# ipro7 register map
Vendor: intelpro; Series: BTBLE
CPU: ipro7, little endian
Registers are 32-bit, read-write, reset 0x0 unless marked. A register's access mark holds for its fields unless they carry their own. Offsets are from the block's base; [hi:lo] are bit positions; {n}, {i} and the like mark numbered series.

## SF_CTRL
Base 0x30081000
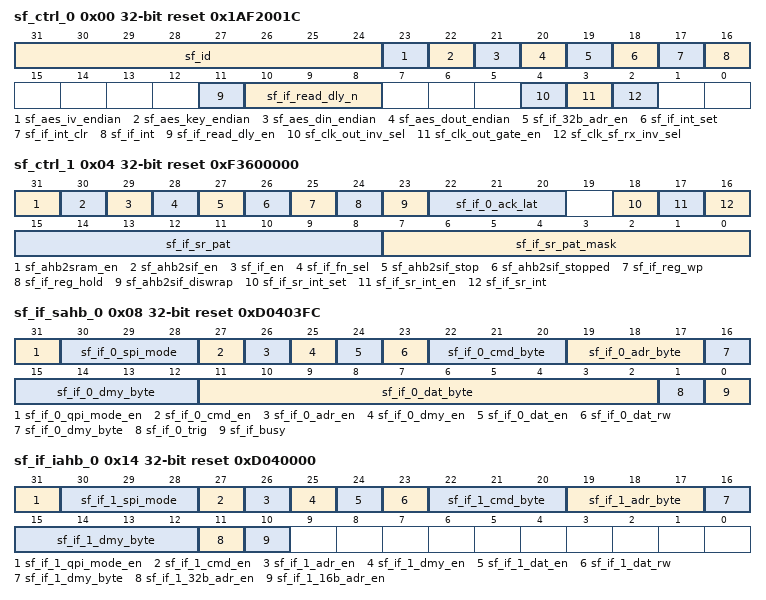
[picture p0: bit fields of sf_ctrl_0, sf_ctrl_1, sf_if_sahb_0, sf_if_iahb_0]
0x00 sf_ctrl_0 reset 0x1AF2001C (reset mask 0xFFFEFFFF)
  [31:24] sf_id — ID
  [23] sf_aes_iv_endian — 0:little-endian 1:big-endian
  [22] sf_aes_key_endian — 0:little-endian 1:big-endian
  [21] sf_aes_din_endian — 0:little-endian 1:big-endian
  [20] sf_aes_dout_endian — 0:little-endian 1:big-endian
  [19] sf_if_32b_adr_en — 1: enable 32-bit address
  [18] sf_if_int_set — 1:set interrupt
  [17] sf_if_int_clr — 1:clear interrupt
  [16] sf_if_int ro — interrupt value
  [11] sf_if_read_dly_en — 1:enable flash controller read delay mode
  [10:8] sf_if_read_dly_n — flash controller read delay cycle = n + 1
  [4] sf_clk_out_inv_sel — 1:select inveted clock out
  [3] sf_clk_out_gate_en — 1:hw auto gated clock out
  [2] sf_clk_sf_rx_inv_sel — 1:select inveted flash rx clock
0x04 sf_ctrl_1 reset 0xF3600000 (reset mask 0xFBFEFFFF)
  [31] sf_ahb2sram_en — 1:enable sram
  [30] sf_ahb2sif_en — 1:enable iahb to flash interface
  [29] sf_if_en — 0:disable sf_if 1:enable sf_if
  [28] sf_if_fn_sel — 0:system ahb 1:icache ahb
  [27] sf_ahb2sif_stop — 1:stop cpu access flash
  [26] sf_ahb2sif_stopped ro — 1:cpu stopped
  [25] sf_if_reg_wp — write protect
  [24] sf_if_reg_hold — hold
  [23] sf_ahb2sif_diswrap — 1:disable iahb to flash wrap access for XTS mode
  [22:20] sf_if_0_ack_lat — ack latency cycles
  [18] sf_if_sr_int_set — 1:set interrupt
  [17] sf_if_sr_int_en — 1:status read interrupt enable
  [16] sf_if_sr_int ro — interrupt value
  [15:8] sf_if_sr_pat — interrupt pattern
  [7:0] sf_if_sr_pat_mask — interrupt mask
0x08 sf_if_sahb_0 reset 0xD0403FC (reset mask 0xFFFFFFFE)
  [31] sf_if_0_qpi_mode_en — 0:normal spi 1:qpi mode enable
  [30:28] sf_if_0_spi_mode — 000:normal spi 001:dual output 010:quad output 011:dual io 100:quad io
  [27] sf_if_0_cmd_en — 1:command enable
  [26] sf_if_0_adr_en — 1:address enable
  [25] sf_if_0_dmy_en — 1:dummy enable
  [24] sf_if_0_dat_en — 1:data enable
  [23] sf_if_0_dat_rw — 0: read 1:write
  [22:20] sf_if_0_cmd_byte — number of command bytes minus 1
  [19:17] sf_if_0_adr_byte — number of address bytes minus 1
  [16:12] sf_if_0_dmy_byte — number of dummy bytes minus 1
  [11:2] sf_if_0_dat_byte — number of command byte minus 1
  [1] sf_if_0_trig — 1:trigger sf_if FSM
  [0] sf_if_busy ro — 1:busy
0x0C sf_if_sahb_1 reset 0x3000000
  [31:0] sf_if_0_cmd_buf_0 — command buffer 0
0x10 sf_if_sahb_2
  [31:0] sf_if_0_cmd_buf_1 — command buffer 1
0x14 sf_if_iahb_0 reset 0xD040000
  [31] sf_if_1_qpi_mode_en — 0:normal spi 1:qpi mode enable
  [30:28] sf_if_1_spi_mode — 000:normal spi 001:dual output 010:quad output 011:dual io 100:quad io
  [27] sf_if_1_cmd_en — 1:command enable
  [26] sf_if_1_adr_en — 1:address enable
  [25] sf_if_1_dmy_en — 1:dummy enable
  [24] sf_if_1_dat_en — 1:data enable
  [23] sf_if_1_dat_rw — 0: read 1:write
  [22:20] sf_if_1_cmd_byte — number of command bytes minus 1
  [19:17] sf_if_1_adr_byte — number of address bytes minus 1
  [16:12] sf_if_1_dmy_byte — number of dummy bytes minus 1
  [11] sf_if_1_32b_adr_en — 1: enable 32-bit address
  [10] sf_if_1_16b_adr_en — 1: enable 16-bit address
0x18 sf_if_iahb_1 reset 0x3000000
  [31:0] sf_if_1_cmd_buf_0 — command buffer 0
0x1C sf_if_iahb_2
  [31:0] sf_if_1_cmd_buf_1 — command buffer 1
0x20 sf_if_status_0 reset not defined
  [31:0] sf_if_status_0 ro
0x24 sf_if_status_1 reset 0x20000000 (reset mask 0x0)
  [31:0] sf_if_status_1 ro
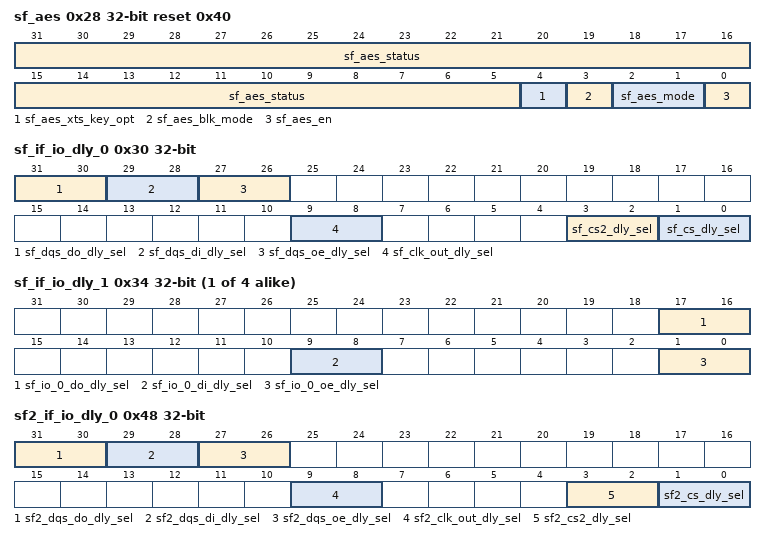
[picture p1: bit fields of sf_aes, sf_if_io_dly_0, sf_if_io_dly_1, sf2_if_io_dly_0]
0x28 sf_aes reset 0x40 (reset mask 0x1F)
  [31:5] sf_aes_status ro
  [4] sf_aes_xts_key_opt — 0:xts accelerate option on 1:0:xts accelerate option off
  [3] sf_aes_blk_mode — 0:CTR mode 1:XTS mode
  [2:1] sf_aes_mode — 0:128-bit mode 1:256-bit mode 2:192-bit mode 3:128-bit double key mode
  [0] sf_aes_en — 0:disable 1:enable aes
0x2C sf_ahb2sif_status reset 0x1010003 (reset mask 0x0)
  [31:0] sf_ahb2sif_status ro
0x30 sf_if_io_dly_0
  [31:30] sf_dqs_do_dly_sel — io delay selection
  [29:28] sf_dqs_di_dly_sel — io delay selection
  [27:26] sf_dqs_oe_dly_sel — io delay selection
  [9:8] sf_clk_out_dly_sel — io delay selection
  [3:2] sf_cs2_dly_sel — io delay selection
  [1:0] sf_cs_dly_sel — io delay selection
{0x30+4i} sf_if_io_dly_{i} (i=1..4)
  [17:16] sf_io_{i-1}_do_dly_sel — io delay selection
  [9:8] sf_io_{i-1}_di_dly_sel — io delay selection
  [1:0] sf_io_{i-1}_oe_dly_sel — io delay selection
0x44 sf_reserved reset 0xFFFF
0x48 sf2_if_io_dly_0
  [31:30] sf2_dqs_do_dly_sel — io delay selection
  [29:28] sf2_dqs_di_dly_sel — io delay selection
  [27:26] sf2_dqs_oe_dly_sel — io delay selection
  [9:8] sf2_clk_out_dly_sel — io delay selection
  [3:2] sf2_cs2_dly_sel — io delay selection
  [1:0] sf2_cs_dly_sel — io delay selection
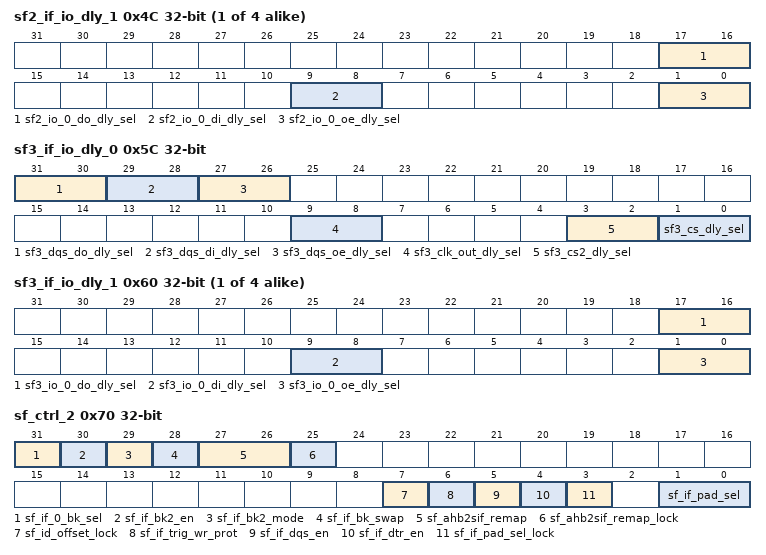
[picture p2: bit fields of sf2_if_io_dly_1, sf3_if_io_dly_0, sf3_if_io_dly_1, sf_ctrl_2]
{0x48+4i} sf2_if_io_dly_{i} (i=1..4)
  [17:16] sf2_io_{i-1}_do_dly_sel — io delay selection
  [9:8] sf2_io_{i-1}_di_dly_sel — io delay selection
  [1:0] sf2_io_{i-1}_oe_dly_sel — io delay selection
0x5C sf3_if_io_dly_0
  [31:30] sf3_dqs_do_dly_sel — io delay selection
  [29:28] sf3_dqs_di_dly_sel — io delay selection
  [27:26] sf3_dqs_oe_dly_sel — io delay selection
  [9:8] sf3_clk_out_dly_sel — io delay selection
  [3:2] sf3_cs2_dly_sel — io delay selection
  [1:0] sf3_cs_dly_sel — io delay selection
{0x5C+4i} sf3_if_io_dly_{i} (i=1..4)
  [17:16] sf3_io_{i-1}_do_dly_sel — io delay selection
  [9:8] sf3_io_{i-1}_di_dly_sel — io delay selection
  [1:0] sf3_io_{i-1}_oe_dly_sel — io delay selection
0x70 sf_ctrl_2
  [31] sf_if_0_bk_sel — 0:system bus select bank0, 1:system bus select bank1
  [30] sf_if_bk2_en — 1:enable 2nd bank
  [29] sf_if_bk2_mode — 0:dual cs mode, 1:dual bank mode
  [28] sf_if_bk_swap — 1:swap 1st bank and 2nd bank
  [27:26] sf_ahb2sif_remap — 0:original memory map 1:remap HADDR>16MB region to psram port HADDR[24] -> HADDR[28] 2:remap HADDR>8MB region to psram port HADDR[23] -> HADDR[28] 3:remap HADDR>4MB region to psram port HADDR[22] -> HADDR[28]
  [25] sf_ahb2sif_remap_lock — sf pad selection lock
  [7] sf_id_offset_lock — lock for sf_id0_offset / sf_id1_offset / sf_bk2_id0_offset / sf_bk2_id1_offset
  [6] sf_if_trig_wr_prot — protect sf_if_0_trig_wr_lock/sf_if2_0_trig_wr_lock for write command only
  [5] sf_if_dqs_en — 1:enable dqs mode
  [4] sf_if_dtr_en — 1:enable dtr mode
  [3] sf_if_pad_sel_lock — sf pad selection lock
  [1:0] sf_if_pad_sel — sf pad selection sf_if_bk2_mode=0 -> 0:pad select sf 1:pad select sf2 2:pad select sf3 sf_if_bk2_mode=1 -> 0:pad select sf/sf2 1:pad select sf2/sf3 2:pad select sf3/sf
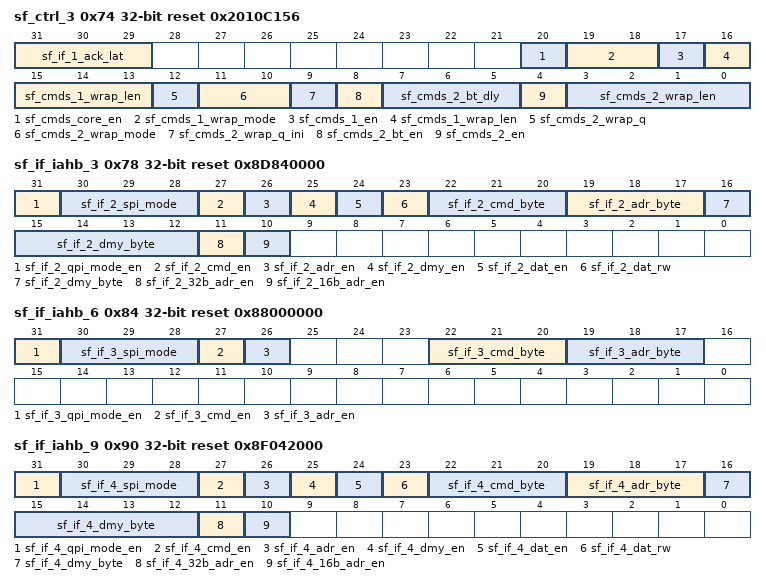
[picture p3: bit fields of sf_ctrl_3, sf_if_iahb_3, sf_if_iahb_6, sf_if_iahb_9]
0x74 sf_ctrl_3 reset 0x2010C156 (reset mask 0xFFFFEFFF)
  [31:29] sf_if_1_ack_lat — ack latency cycles
  [20] sf_cmds_core_en — 1:enable command splitter core
  [19:18] sf_cmds_1_wrap_mode — [0]0:cmds bypass wrap commands to macro, 1:cmds handle wrap commands [1]0:original mode, 1:cmds force wrap16x4 splitted into two wrap8x4
  [17] sf_cmds_1_en — 1:enable command splitter
  [16:13] sf_cmds_1_wrap_len — wrap length 0:8, 1:16, 2:32, 3:64, 4:128, 5:256, 6:512, 7:1024, 8:2048, 9:4096
  [12] sf_cmds_2_wrap_q ro — wrap queue value
  [11:10] sf_cmds_2_wrap_mode — [0]0:cmds bypass wrap commands to macro, 1:cmds handle wrap commands [1]0:original mode, 1:cmds force wrap16x4 splitted into two wrap8x4
  [9] sf_cmds_2_wrap_q_ini — wrap queue initial value
  [8] sf_cmds_2_bt_en — 1:enable command splitter burst toggle mode
  [7:5] sf_cmds_2_bt_dly — dummy delay cycle after burst toggle command
  [4] sf_cmds_2_en — 1:enable command splitter
  [3:0] sf_cmds_2_wrap_len — wrap length 0:8, 1:16, 2:32, 3:64, 4:128, 5:256, 6:512, 7:1024, 8:2048, 9:4096
0x78 sf_if_iahb_3 reset 0x8D840000
  [31] sf_if_2_qpi_mode_en — 0:normal spi 1:qpi mode enable
  [30:28] sf_if_2_spi_mode — 000:normal spi 001:dual output 010:quad output 011:dual io 100:quad io
  [27] sf_if_2_cmd_en — 1:command enable
  [26] sf_if_2_adr_en — 1:address enable
  [25] sf_if_2_dmy_en — 1:dummy enable
  [24] sf_if_2_dat_en — 1:data enable
  [23] sf_if_2_dat_rw — 0: read 1:write
  [22:20] sf_if_2_cmd_byte — number of command bytes minus 1
  [19:17] sf_if_2_adr_byte — number of address bytes minus 1
  [16:12] sf_if_2_dmy_byte — number of dummy bytes minus 1
  [11] sf_if_2_32b_adr_en — 1: enable 32-bit address
  [10] sf_if_2_16b_adr_en — 1: enable 16-bit address
0x7C sf_if_iahb_4 reset 0x38000000
  [31:0] sf_if_2_cmd_buf_0 — command buffer 0
0x80 sf_if_iahb_5
  [31:0] sf_if_2_cmd_buf_1 — command buffer 1
0x84 sf_if_iahb_6 reset 0x88000000
  [31] sf_if_3_qpi_mode_en — 0:normal spi 1:qpi mode enable
  [30:28] sf_if_3_spi_mode — 000:normal spi 001:dual output 010:quad output 011:dual io 100:quad io
  [27] sf_if_3_cmd_en — 1:command enable
  [26] sf_if_3_adr_en — 1:address enable
  [22:20] sf_if_3_cmd_byte — number of command bytes minus 1
  [19:17] sf_if_3_adr_byte — number of address bytes minus 1
0x88 sf_if_iahb_7 reset 0xC0000000
  [31:0] sf_if_3_cmd_buf_0 — command buffer 0
0x8C sf_if_iahb_8
  [31:0] sf_if_3_cmd_buf_1 — command buffer 1
0x90 sf_if_iahb_9 reset 0x8F042000
  [31] sf_if_4_qpi_mode_en — 0:normal spi 1:qpi mode enable
  [30:28] sf_if_4_spi_mode — 000:normal spi 001:dual output 010:quad output 011:dual io 100:quad io
  [27] sf_if_4_cmd_en — 1:command enable
  [26] sf_if_4_adr_en — 1:address enable
  [25] sf_if_4_dmy_en — 1:dummy enable
  [24] sf_if_4_dat_en — 1:data enable
  [23] sf_if_4_dat_rw — 0: read 1:write
  [22:20] sf_if_4_cmd_byte — number of command bytes minus 1
  [19:17] sf_if_4_adr_byte — number of address bytes minus 1
  [16:12] sf_if_4_dmy_byte — number of dummy bytes minus 1
  [11] sf_if_4_32b_adr_en — 1: enable 32-bit address
  [10] sf_if_4_16b_adr_en — 1: enable 16-bit address
0x94 sf_if_iahb_10 reset 0xEB000000
  [31:0] sf_if_4_cmd_buf_0 — command buffer 0
0x98 sf_if_iahb_11
  [31:0] sf_if_4_cmd_buf_1 — command buffer 1
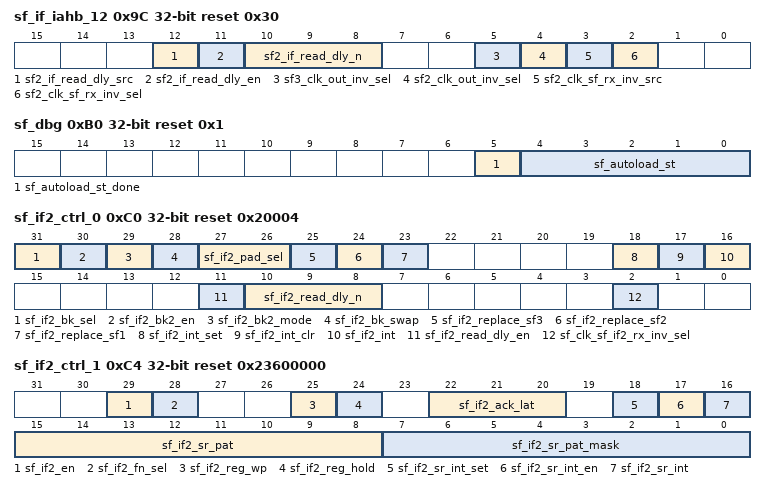
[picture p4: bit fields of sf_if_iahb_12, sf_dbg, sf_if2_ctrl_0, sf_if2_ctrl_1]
0x9C sf_if_iahb_12 reset 0x30
  [12] sf2_if_read_dly_src — 0:share with sf_if_read_dly 1:use sf2_if_read_dly
  [11] sf2_if_read_dly_en — 1:enable flash controller read delay mode
  [10:8] sf2_if_read_dly_n — flash controller read delay cycle = n + 1
  [5] sf3_clk_out_inv_sel — 1:select inveted clock out
  [4] sf2_clk_out_inv_sel — 1:select inveted clock out
  [3] sf2_clk_sf_rx_inv_src — 0:share with sf_clk_sf_rx_inv_sel 1:use sf2_clk_sf_rx_inv_sel
  [2] sf2_clk_sf_rx_inv_sel — 1:select inveted flash rx clock
0xA0 sf_id0_offset
  [27:0] sf_id0_offset — id0 offset (byte) (from l1c_bmx 0x11)
0xA4 sf_id1_offset
  [27:0] sf_id1_offset — id1 offset (byte) (from l1c_bmx 0x01)
0xA8 sf_bk2_id0_offset
  [27:0] sf_bk2_id0_offset — id0 offset (byte)
0xAC sf_bk2_id1_offset
  [27:0] sf_bk2_id1_offset — id1 offset (byte)
0xB0 sf_dbg reset 0x1 (reset mask 0xFFFFFFC0)
  [5] sf_autoload_st_done ro, [4:0] sf_autoload_st ro
0xC0 sf_if2_ctrl_0 reset 0x20004 (reset mask 0xFFFEFFFF)
  [31] sf_if2_bk_sel — 0:system bus select bank0, 1:system bus select bank1
  [30] sf_if2_bk2_en — 1:enable 2nd bank
  [29] sf_if2_bk2_mode — 0:dual cs mode, 1:dual bank mode
  [28] sf_if2_bk_swap — 1:swap 1st bank and 2nd bank
  [27:26] sf_if2_pad_sel — sf pad selection sf_if_bk2_mode=0 -> 0:pad select sf 1:pad select sf2 2:pad select sf3 sf_if_bk2_mode=1 -> 0:pad select sf/sf2 1:pad select sf2/sf3 2:pad select sf3/sf
  [25] sf_if2_replace_sf3 — 1:use sf_if2 replace sf3 when sf_if2_fn_sel=1
  [24] sf_if2_replace_sf2 — 1:use sf_if2 replace sf2 when sf_if2_fn_sel=1
  [23] sf_if2_replace_sf1 — 1:use sf_if2 replace sf1 when sf_if2_fn_sel=1
  [18] sf_if2_int_set — 1:set interrupt
  [17] sf_if2_int_clr — 1:clear interrupt
  [16] sf_if2_int ro — interrupt value
  [11] sf_if2_read_dly_en — 1:enable flash controller read delay mode
  [10:8] sf_if2_read_dly_n — flash controller read delay cycle = n + 1
  [2] sf_clk_sf_if2_rx_inv_sel — 1:select inveted flash rx clock
0xC4 sf_if2_ctrl_1 reset 0x23600000 (reset mask 0xFFFEFFFF)
  [29] sf_if2_en — 0:disable sf_if2 1:enable sf_if2
  [28] sf_if2_fn_sel — 1:function select sf_if2
  [25] sf_if2_reg_wp — write protect
  [24] sf_if2_reg_hold — hold
  [22:20] sf_if2_ack_lat — ack latency cycles
  [18] sf_if2_sr_int_set — 1:set interrupt
  [17] sf_if2_sr_int_en — 1:status read interrupt enable
  [16] sf_if2_sr_int ro — interrupt value
  [15:8] sf_if2_sr_pat — interrupt pattern
  [7:0] sf_if2_sr_pat_mask — interrupt mask
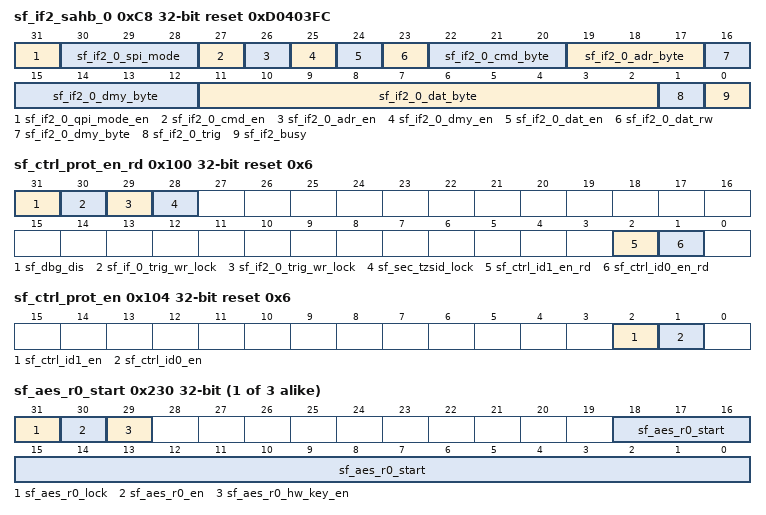
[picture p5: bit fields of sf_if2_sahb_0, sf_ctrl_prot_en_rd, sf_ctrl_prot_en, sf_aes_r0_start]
0xC8 sf_if2_sahb_0 reset 0xD0403FC (reset mask 0xFFFFFFFE)
  [31] sf_if2_0_qpi_mode_en — 0:normal spi 1:qpi mode enable
  [30:28] sf_if2_0_spi_mode — 000:normal spi 001:dual output 010:quad output 011:dual io 100:quad io
  [27] sf_if2_0_cmd_en — 1:command enable
  [26] sf_if2_0_adr_en — 1:address enable
  [25] sf_if2_0_dmy_en — 1:dummy enable
  [24] sf_if2_0_dat_en — 1:data enable
  [23] sf_if2_0_dat_rw — 0: read 1:write
  [22:20] sf_if2_0_cmd_byte — number of command bytes minus 1
  [19:17] sf_if2_0_adr_byte — number of address bytes minus 1
  [16:12] sf_if2_0_dmy_byte — number of dummy bytes minus 1
  [11:2] sf_if2_0_dat_byte — number of command byte minus 1
  [1] sf_if2_0_trig — 1:trigger sf_if FSM
  [0] sf_if2_busy ro — 1:busy
0xCC sf_if2_sahb_1 reset 0x3000000
  [31:0] sf_if2_0_cmd_buf_0 — command buffer 0
0xD0 sf_if2_sahb_2
  [31:0] sf_if2_0_cmd_buf_1 — command buffer 1
0x100 sf_ctrl_prot_en_rd reset 0x6 (reset mask 0xFFFFFF9)
  [31] sf_dbg_dis ro — 1:disable aes debug mode
  [30] sf_if_0_trig_wr_lock ro — sf_if_0_trig write protect for TZC
  [29] sf_if2_0_trig_wr_lock ro — sf_if_0_trig write protect for TZC
  [28] sf_sec_tzsid_lock ro
  [2] sf_ctrl_id1_en_rd ro — read only status of id1 access right
  [1] sf_ctrl_id0_en_rd ro — read only status of id0 access right
0x104 sf_ctrl_prot_en reset 0x6
  [2] sf_ctrl_id1_en — id1 access right
  [1] sf_ctrl_id0_en — id0 access right
{0x200+0x80*i} sf_aes_key_r{i}_0 (i=0..2)
  [31:0] sf_aes_key_r{i}_0 — big endian aes key (aes-128/256 key MSB)
{0x204+0x80*i} sf_aes_key_r{i}_1 (i=0..2)
  [31:0] sf_aes_key_r{i}_1 — big endian aes key
{0x208+0x80*i} sf_aes_key_r{i}_2 (i=0..2)
  [31:0] sf_aes_key_r{i}_2 — big endian aes key
{0x20C+0x80*i} sf_aes_key_r{i}_3 (i=0..2)
  [31:0] sf_aes_key_r{i}_3 — big endian aes key (aes-128 key LSB)
{0x210+0x80*i} sf_aes_key_r{i}_4 (i=0..2)
  [31:0] sf_aes_key_r{i}_4 — big endian aes key
{0x214+0x80*i} sf_aes_key_r{i}_5 (i=0..2)
  [31:0] sf_aes_key_r{i}_5 — big endian aes key
{0x218+0x80*i} sf_aes_key_r{i}_6 (i=0..2)
  [31:0] sf_aes_key_r{i}_6 — big endian aes key
{0x21C+0x80*i} sf_aes_key_r{i}_7 (i=0..2)
  [31:0] sf_aes_key_r{i}_7 — big endian aes key (aes-256 key LSB)
{0x220+0x80*i} sf_aes_iv_r{i}_w0 (i=0..2)
  [31:0] sf_aes_iv_r{i}_w0 — big endian iv (MSB)
{0x224+0x80*i} sf_aes_iv_r{i}_w1 (i=0..2)
  [31:0] sf_aes_iv_r{i}_w1 — big endian iv
{0x228+0x80*i} sf_aes_iv_r{i}_w2 (i=0..2)
  [31:0] sf_aes_iv_r{i}_w2 — big endian iv (LSB)
{0x22C+0x80*i} sf_aes_iv_r{i}_w3 (i=0..2)
  [31:0] sf_aes_iv_r{i}_w3 — big endian 32-bit counter offset
{0x230+0x80*i} sf_aes_r{i}_start (i=0..2)
  [31] sf_aes_r{i}_lock — 1:lock region setting
  [30] sf_aes_r{i}_en — 1:enable region
  [29] sf_aes_r{i}_hw_key_en — 0:sw key 1:hw key
  [18:0] sf_aes_r{i}_start — 1k byte align
{0x234+0x80*i} sf_aes_r{i}_end reset 0x3FFF (i=0..2)
  [18:0] sf_aes_r{i}_end — 1k byte align
